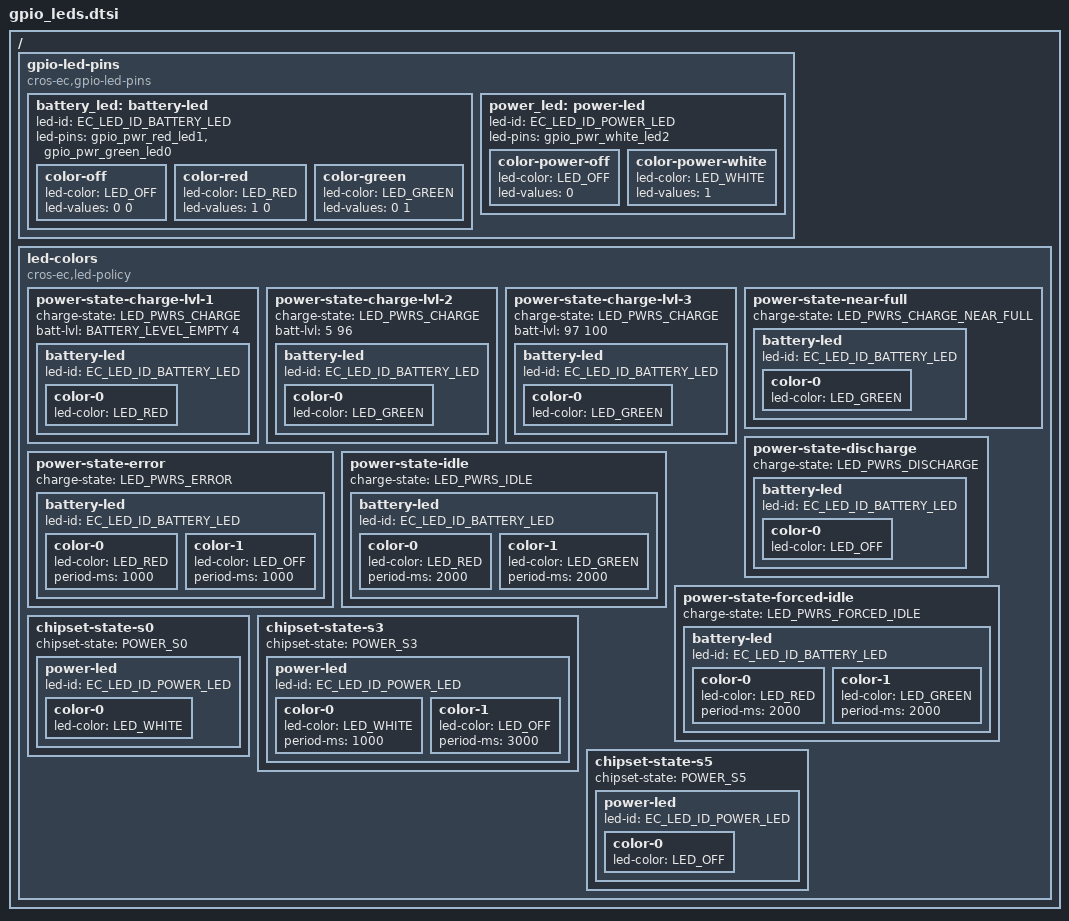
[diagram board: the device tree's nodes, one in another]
/* Copyright 2025 The ChromiumOS Authors
 * Use of this source code is governed by a BSD-style license that can be
 * found in the LICENSE file.
 */
#include <dt-bindings/battery.h>

/ {
	gpio-led-pins {
		compatible = "cros-ec,gpio-led-pins";

		battery_led: battery-led {
			led-id = "EC_LED_ID_BATTERY_LED";
			led-pins = <&gpio_pwr_red_led1 &gpio_pwr_green_led0>;

			color-off {
				led-color = "LED_OFF";
				led-values = <0 0>;
			};

			color-red {
				led-color = "LED_RED";
				led-values = <1 0>;
			};

			color-green {
				led-color = "LED_GREEN";
				led-values = <0 1>;
			};
		};

		power_led: power-led {
			led-id = "EC_LED_ID_POWER_LED";
			led-pins = <&gpio_pwr_white_led2>;

			color-power-off {
				led-color = "LED_OFF";
				led-values = <0>;
			};

			color-power-white {
				led-color = "LED_WHITE";
				led-values = <1>;
			};
		};

	};

	led-colors {
		compatible = "cros-ec,led-policy";

		power-state-charge-lvl-1 {
			charge-state = "LED_PWRS_CHARGE";

			/* Battery display percent range (>= Empty, <= 4%) */
			batt-lvl = <BATTERY_LEVEL_EMPTY 4>;

			battery-led {
				led-id = "EC_LED_ID_BATTERY_LED";

				color-0 {
					led-color = "LED_RED";
				};
			};
		};

		power-state-charge-lvl-2 {
			charge-state = "LED_PWRS_CHARGE";

			/* Battery display percent range (>= 5%, <= 96%) */
			batt-lvl = <5 96>;

			battery-led {
				led-id = "EC_LED_ID_BATTERY_LED";

				color-0 {
					led-color = "LED_GREEN";
				};
			};
		};

		power-state-charge-lvl-3 {
			charge-state = "LED_PWRS_CHARGE";

			/* Battery display percent range (>= 97) */
			batt-lvl = <97 100>;

			battery-led {
				led-id = "EC_LED_ID_BATTERY_LED";

				color-0 {
					led-color = "LED_GREEN";
				};
			};
		};

		power-state-near-full {
			charge-state = "LED_PWRS_CHARGE_NEAR_FULL";

			battery-led {
				led-id = "EC_LED_ID_BATTERY_LED";

				color-0 {
					led-color = "LED_GREEN";
				};
			};
		};

		power-state-discharge {
			charge-state = "LED_PWRS_DISCHARGE";

			battery-led {
				led-id = "EC_LED_ID_BATTERY_LED";

				color-0 {
					led-color = "LED_OFF";
				};
			};
		};

		power-state-error {
			charge-state = "LED_PWRS_ERROR";

			battery-led {
				led-id = "EC_LED_ID_BATTERY_LED";

				/* Red 1 sec on, 1 sec off */
				color-0 {
					led-color = "LED_RED";
					period-ms = <1000>;
				};
				color-1 {
					led-color = "LED_OFF";
					period-ms = <1000>;
				};
			};
		};

		/* PUJJONIRU LED power idle */
		power-state-idle {
			charge-state = "LED_PWRS_IDLE";

			battery-led {
				led-id = "EC_LED_ID_BATTERY_LED";

				/* Red 2 sec on, Green 2 sec on */
				color-0 {
					led-color = "LED_RED";
					period-ms = <2000>;
				};
				color-1 {
					led-color = "LED_GREEN";
					period-ms = <2000>;
				};
			};
		};

		/* PUJJONIRU LED power forced idle */
		power-state-forced-idle {
			charge-state = "LED_PWRS_FORCED_IDLE";

			battery-led {
				led-id = "EC_LED_ID_BATTERY_LED";

				/* Red 2 sec on, Green 2 sec on */
				color-0 {
					led-color = "LED_RED";
					period-ms = <2000>;
				};
				color-1 {
					led-color = "LED_GREEN";
					period-ms = <2000>;
				};
			};
		};

		chipset-state-s0 {
			chipset-state = "POWER_S0";

			power-led {
				led-id = "EC_LED_ID_POWER_LED";

				color-0 {
					led-color = "LED_WHITE";
				};
			};
		};

		chipset-state-s3 {
			chipset-state = "POWER_S3";

			power-led {
				led-id = "EC_LED_ID_POWER_LED";

				/* White 1 sec on, 3 sec off */
				color-0 {
					led-color = "LED_WHITE";
					period-ms = <1000>;
				};
				color-1 {
					led-color = "LED_OFF";
					period-ms = <3000>;
				};
			};
		};

		chipset-state-s5 {
			chipset-state = "POWER_S5";

			power-led {
				led-id = "EC_LED_ID_POWER_LED";

				color-0 {
					led-color = "LED_OFF";
				};
			};
		};
	};
};
